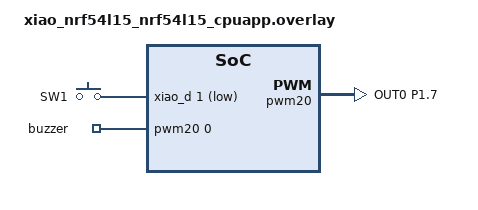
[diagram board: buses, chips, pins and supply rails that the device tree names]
/ {
    buttons {
        compatible = "gpio-keys";
        xiao_button0: button_0 {
            gpios = <&xiao_d 1 (GPIO_PULL_UP | GPIO_ACTIVE_LOW)>;
            label = "SW1";
            zephyr,code = <INPUT_KEY_0>;
        };
    };

    // use pwm-led to control buzzer 
    pwm_leds {
        compatible = "pwm-leds";
        buzzer: buzzer {
            pwms = <&pwm20 0 PWM_MSEC(20) PWM_POLARITY_NORMAL>;
            status = "okay";
        };
    };
    
    aliases {
        sw1 = &xiao_button0;
        buzzer = &buzzer;
    };
};

&pwm20 {
    status = "okay";
	pinctrl-0 = <&pwm20_default>;
	pinctrl-1 = <&pwm20_sleep>;
	pinctrl-names = "default", "sleep";
};

&pinctrl {
    pwm20_default: pwm20_default {
		group1 {
            // GPIO D3 = P1.7 on XIAO nRF54L15 
			psels = <NRF_PSEL(PWM_OUT0, 1, 7)>;
		};
	};

    pwm20_sleep: pwm20_sleep {
		group1 {
			psels = <NRF_PSEL(PWM_OUT0, 1, 7)>;
			low-power-enable;
		};
	};
};
